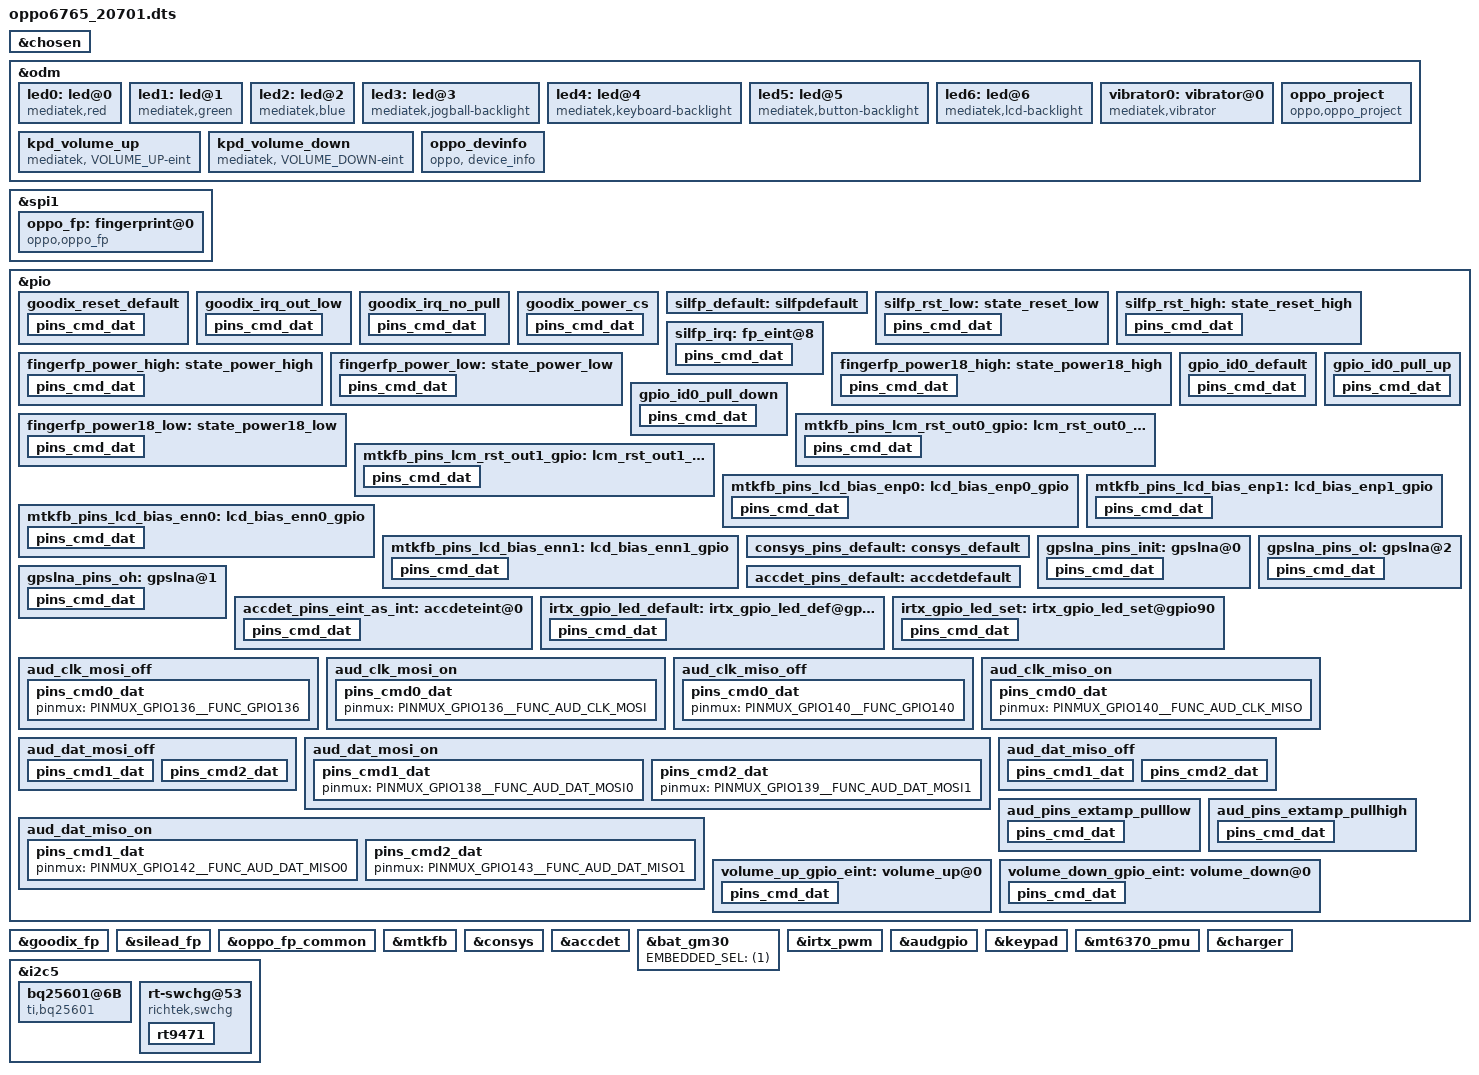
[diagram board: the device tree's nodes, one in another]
/*
 * Copyright (C) 2019 MediaTek Inc.
 *
 * This program is free software; you can redistribute it and/or modify
 * it under the terms of the GNU General Public License version 2 as
 * published by the Free Software Foundation.
 *
 * This program is distributed in the hope that it will be useful,
 * but WITHOUT ANY WARRANTY; without even the implied warranty of
 * MERCHANTABILITY or FITNESS FOR A PARTICULAR PURPOSE.
 * See http://www.gnu.org/licenses/gpl-2.0.html for more details.
 */

#include <dt-bindings/interrupt-controller/arm-gic.h>
#include <dt-bindings/interrupt-controller/irq.h>
#include <dt-bindings/pinctrl/mt6765-pinfunc.h>
#include <dt-bindings/clock/mt6765-clk.h>

/dts-v1/;
/plugin/;

/* chosen */
&chosen {

	/* fpga may has no lk, we need to specify display info here */
	/* fb buffer is reserved using this dts by memory node above */
	atag,videolfb-fb_base_h = <0x0>;
	atag,videolfb-fb_base_l = <0x5e605000>;
	atag,videolfb-islcmfound = <1>;
	/* because no lk, so lcm is not inited */
	atag,videolfb-islcm_inited = <0>;
	atag,videolfb-fps= <6000>;
	atag,videolfb-vramSize= <0x017bb000>;
	atag,videolfb-lcmname= "nt35695B_fhd_dsi_cmd_auo_rt5081_drv";
};

&odm {
	led0:led@0 {
		compatible = "mediatek,red";
		led_mode = <0>;
		data = <1>;
		pwm_config = <0 0 0 0 0>;
	};
	led1:led@1 {
		compatible = "mediatek,green";
		led_mode = <0>;
		data = <1>;
		pwm_config = <0 0 0 0 0>;
	};
	led2:led@2 {
		compatible = "mediatek,blue";
		led_mode = <0>;
		data = <1>;
		pwm_config = <0 0 0 0 0>;
	};
	led3:led@3 {
		compatible = "mediatek,jogball-backlight";
		led_mode = <0>;
		data = <1>;
		pwm_config = <0 0 0 0 0>;
	};
	led4:led@4 {
		compatible = "mediatek,keyboard-backlight";
		led_mode = <0>;
		data = <1>;
		pwm_config = <0 0 0 0 0>;
	};
	led5:led@5 {
		compatible = "mediatek,button-backlight";
		led_mode = <0>;
		data = <1>;
		pwm_config = <0 0 0 0 0>;
	};
	led6:led@6 {
		compatible = "mediatek,lcd-backlight";
	//#ifndef ODM_HQ_EDIT
	//wangcheng@ODM.Multimedia.LCD  2020/08/31 modify for lcd-bl mode
	led_mode = <4>;
	//#endif
		data = <1>;
		pwm_config = <0 3 0 0 0>;
	};
	vibrator0:vibrator@0 {
		compatible = "mediatek,vibrator";
		/*
		vib_timer = <25>;
		vib_limit = <9>;
		vib_vol= <9>;
		*/
		vib_timer = <30>;
		vib_limit = <0>;
                vib_vol= <11>;		
	};

	oppo_project:oppo_project {
		compatible = "oppo,oppo_project";
	};
//#ifdef VENDOR_EDIT
/* Bin.Li@EXP.BSP.bootloader.bootflow, 2017/05/16, Add volume up and down */
       kpd_volume_up:kpd_volume_up {
               compatible = "mediatek, VOLUME_UP-eint";
               interrupt-parent = <&pio>;
               interrupts = <20 IRQ_TYPE_EDGE_FALLING 20 0>;
               debounce = <32000>;
               status = "okay";
       };

       kpd_volume_down:kpd_volume_down {
               compatible = "mediatek, VOLUME_DOWN-eint";
               interrupt-parent = <&pio>;
               interrupts = <94 IRQ_TYPE_EDGE_FALLING 94 0>;
               debounce = <32000>;
               status = "okay";
       };
//#endif
	oppo_devinfo:oppo_devinfo {
		compatible = "oppo, device_info";
		sub_board-gpio = <&pio 43 0>;
		sdcard-gpio = <&pio 1 0>;
	};
};

&spi1 {
	#address-cells = <1>;
	#size-cells = <0>;
	status = "okay";
	oppo_fp: fingerprint@0 {
	    compatible = "oppo,oppo_fp";
	    reg = <0>;
	    spi-max-frequency = <8000000>;
	    netlink-event = <30>;
	    spi-id = <1>;
	    spi-irq = <122>;
	    spi-reg = <0x11010000>;
        status = "okay";
    };
};
&pio {
	goodix_reset_default: goodix_reset_default {
		pins_cmd_dat {
			pinmux = <PINMUX_GPIO171__FUNC_GPIO171>;
			slew-rate = <1>;
			output-low;
		};
	};
	goodix_irq_out_low: goodix_irq_out_low {
		pins_cmd_dat {
			pinmux = <PINMUX_GPIO3__FUNC_GPIO3>;
			slew-rate = <1>;
			output-low;
		};
	};
	goodix_irq_no_pull: goodix_irq_no_pull {
		pins_cmd_dat {
			pinmux = <PINMUX_GPIO3__FUNC_GPIO3>;
			slew-rate = <0>;
			bias-disable;
		};
	};
	goodix_power_cs: goodix_power_cs {
		pins_cmd_dat {
			pinmux = <PINMUX_GPIO158__FUNC_GPIO158>;
			slew-rate = <1>;
			bias-disable;
			output-high;
		};
	};    
};
&goodix_fp {
	pinctrl-names = "goodix_reset_default", "goodix_irq_out_low", "goodix_irq_no_pull", "goodix_power_cs";
	pinctrl-0 = <&goodix_reset_default>;
	pinctrl-1 = <&goodix_irq_out_low>;
	pinctrl-2 = <&goodix_irq_no_pull>;
    pinctrl-3 = <&goodix_power_cs>;
	interrupt-parent = <&pio>;
	interrupts = <3 0>;
	goodix,gpio_irq = <&pio 3 0x00>;
	goodix,gpio_reset = <&pio 171 0x00>;
    goodix,vdd-en = <&pio 158 0x00>;
	spi-max-frequency = <8000000>;
	status = "okay";
};

/*-------------------the goodix device config end----------------------*/

/*-------------------the silead device config start----------------------*/
&pio {
	silfp_default: silfpdefault {
	};
	silfp_rst_low: state_reset_low {
		pins_cmd_dat {
			pinmux = <PINMUX_GPIO171__FUNC_GPIO171>;
			slew-rate = <1>;
			output-low;
		};
	};
	silfp_rst_high: state_reset_high {
		pins_cmd_dat {
			pinmux = <PINMUX_GPIO171__FUNC_GPIO171>;
			slew-rate = <1>;
			output-high;
		};
	};
	silfp_irq: fp_eint@8 {
		pins_cmd_dat {
			pinmux = <PINMUX_GPIO3__FUNC_GPIO3>;
			slew-rate = <0>;
			bias-disable;
		};
	};
	fingerfp_power_high: state_power_high {
		pins_cmd_dat {
			pinmux = <PINMUX_GPIO158__FUNC_GPIO158>;
			slew-rate = <1>;
			output-high;
		};
	};

	fingerfp_power_low: state_power_low {
		pins_cmd_dat {
			pinmux = <PINMUX_GPIO158__FUNC_GPIO158>;
			slew-rate = <1>;
			output-low;
		};
	};
	fingerfp_power18_high: state_power18_high {
		pins_cmd_dat {
			pinmux = <PINMUX_GPIO158__FUNC_GPIO158>;
			slew-rate = <1>;
			output-high;
		};
	};

	fingerfp_power18_low: state_power18_low {
		pins_cmd_dat {
			pinmux = <PINMUX_GPIO79__FUNC_GPIO79>;
			slew-rate = <1>;
			output-low;
		};
	};
};
&silead_fp {
	pinctrl-names = "default", "rst-low", "rst-high",
	                "irq-init", "power_high","power_low", "power18_high","power18_low";
	pinctrl-0 = <&silfp_default>;
	pinctrl-1 = <&silfp_rst_low>;
	pinctrl-2 = <&silfp_rst_high>;
	pinctrl-3 = <&silfp_irq>;
	pinctrl-4 = <&fingerfp_power_high>;
	pinctrl-5 = <&fingerfp_power_low>;
	pinctrl-6 = <&fingerfp_power18_high>;
	pinctrl-7 = <&fingerfp_power18_low>;
	status = "okay";
};
/*-------------------the silead device config end----------------------*/

/*the fingerprint_id config to project dts.*/
&pio{
	gpio_id0_default: gpio_id0_default {
		pins_cmd_dat {
			pinmux = <PINMUX_GPIO170__FUNC_GPIO170>;
			slew-rate = <0>;
			bias-pull-up = <00>;
		};
	};
	gpio_id0_pull_up: gpio_id0_pull_up {
		pins_cmd_dat {
			pinmux = <PINMUX_GPIO170__FUNC_GPIO170>;
			slew-rate = <0>;
			bias-pull-up = <00>;
		};
	};
	gpio_id0_pull_down: gpio_id0_pull_down {
		pins_cmd_dat {
			pinmux = <PINMUX_GPIO170__FUNC_GPIO170>;
			slew-rate = <0>;
			bias-pull-down = <00>;
		};
	};
};

&oppo_fp_common {
	oppo,fp-id0 = <&pio 170 0x00>;
	oppo,fp-id1 = <&pio 173 0x00>;
	pinctrl-names = "default", "gpio_id0_pull_up", "gpio_id0_pull_down";
	pinctrl-0 = <&gpio_id0_default>;
	pinctrl-1 = <&gpio_id0_pull_up>;
	pinctrl-2 = <&gpio_id0_pull_down>;
};

/* TOUCH start */
/*&touch {
	tpd-resolution = <720 1600>;
	use-tpd-button = <0>;
	tpd-key-num = <3>;
	tpd-key-local= <139 172 158 0>;
	tpd-key-dim-local = <90 883 100 40 230
				 883 100 40 370 883 100 40 0 0 0 0>;
	tpd-max-touch-num = <5>;
	tpd-filter-enable = <0>;
	tpd-filter-pixel-density = <146>;
	tpd-filter-custom-prameters = <0 0 0 0 0 0 0 0 0 0 0 0>;
	tpd-filter-custom-speed = <0 0 0>;
	pinctrl-names = "default", "state_eint_as_int", "state_eint_output0",
		"state_eint_output1", "state_rst_output0", "state_rst_output1";
	pinctrl-0 = <&ctp_pins_default>;
	pinctrl-1 = <&ctp_pins_eint_as_int>;
	pinctrl-2 = <&ctp_pins_eint_output0>;
	pinctrl-3 = <&ctp_pins_eint_output1>;
	pinctrl-4 = <&ctp_pins_rst_output0>;
	pinctrl-5 = <&ctp_pins_rst_output1>;
	status = "okay";
};
&pio {
	ctp_pins_default: eint0default {
	};
	ctp_pins_eint_as_int: eint@0 {
		pins_cmd_dat {
			pinmux = <PINMUX_GPIO0__FUNC_GPIO0>;
			slew-rate = <0>;
			bias-disable;
		};
	};
	ctp_pins_eint_output0: eintoutput0 {
		pins_cmd_dat {
			pinmux = <PINMUX_GPIO0__FUNC_GPIO0>;
			slew-rate = <1>;
			output-low;
		};
	};
	ctp_pins_eint_output1: eintoutput1 {
		pins_cmd_dat {
			pinmux = <PINMUX_GPIO0__FUNC_GPIO0>;
			slew-rate = <1>;
			output-high;
		};
	};
	ctp_pins_rst_output0: rstoutput0 {
		pins_cmd_dat {
			pinmux = <PINMUX_GPIO178__FUNC_GPIO178>;
			slew-rate = <1>;
			output-low;
		};
	};
	ctp_pins_rst_output1: rstoutput1 {
		pins_cmd_dat {
			pinmux = <PINMUX_GPIO178__FUNC_GPIO178>;
			slew-rate = <1>;
			output-high;
		};
	};
};*/

//#ifdef ODM_HQ_EDIT
//#Fengkui@ODM_HQ.BSP.Touchscreen.Base,2020/09/08,bringup add for txd touchscreen mould dts config.
//&spi2{
//    #address-cells = <1>;
//    #size-cells = <0>;

//    touch_ts@0 {
//        reg = <0>;
//        compatible = "ilitek,ilitek-ts-spi","novatek,NVT-ts-spi";
//        spi-max-frequency = <9600000>;
//        status = "okay";
//        /* touch spi config */
//		touch,reset-gpio = <&pio 178 0x00>;
//		touch,irq-gpio = <&pio 0 0x2002>;
//		novatek,reset-gpio = <&pio 178 0x00>;
//		novatek,irq-gpio = <&pio 0 0x2002>;
//		novatek,swrst-n8-addr = <0x03F0FE>;
//              };
//     };
//#endif
/* TOUCH end */

/* wangcheng@ODM.Multimedia.LCD  2020/08/31 add  for lcd  bringup  start  */
/* DISPSYS GPIO standardization */
&pio {
	mtkfb_pins_lcm_rst_out0_gpio: lcm_rst_out0_gpio {
		pins_cmd_dat {
			pinmux = <PINMUX_GPIO45__FUNC_GPIO45>;
			slew-rate = <1>;
			output-low;
		};
	};
	
	mtkfb_pins_lcm_rst_out1_gpio: lcm_rst_out1_gpio {
		pins_cmd_dat {
			pinmux = <PINMUX_GPIO45__FUNC_GPIO45>;
			slew-rate = <1>;
			output-high;
		};
	};

	mtkfb_pins_lcd_bias_enp0: lcd_bias_enp0_gpio {
		pins_cmd_dat {
			pinmux = <PINMUX_GPIO166__FUNC_GPIO166>;
			slew-rate = <1>;
			output-low;
		};
	};

	mtkfb_pins_lcd_bias_enp1: lcd_bias_enp1_gpio {
		pins_cmd_dat {
			pinmux = <PINMUX_GPIO166__FUNC_GPIO166>;
			slew-rate = <1>;
			output-high;
		};
	};

	mtkfb_pins_lcd_bias_enn0: lcd_bias_enn0_gpio {
		pins_cmd_dat {
			pinmux = <PINMUX_GPIO165__FUNC_GPIO165>;
			slew-rate = <1>;
			output-low;
		};
	};

	mtkfb_pins_lcd_bias_enn1: lcd_bias_enn1_gpio {
		pins_cmd_dat {
			pinmux = <PINMUX_GPIO165__FUNC_GPIO165>;
			slew-rate = <1>;
			output-high;
		};
	};
};

&mtkfb {
	pinctrl-names = "lcm_rst_out0_gpio", "lcm_rst_out1_gpio",
		"lcd_bias_enp0_gpio", "lcd_bias_enp1_gpio", 
		 "lcd_bias_enn0_gpio", "lcd_bias_enn1_gpio";
	pinctrl-0 = <&mtkfb_pins_lcm_rst_out0_gpio>;
	pinctrl-1 = <&mtkfb_pins_lcm_rst_out1_gpio>;
	pinctrl-2 = <&mtkfb_pins_lcd_bias_enp0>;
	pinctrl-3 = <&mtkfb_pins_lcd_bias_enp1>;
	pinctrl-4 = <&mtkfb_pins_lcd_bias_enn0>;
	pinctrl-5 = <&mtkfb_pins_lcd_bias_enn1>;
	status = "okay";
};

/* DISPSYS GPIO standardization end */
/* wangcheng@ODM.Multimedia.LCD  2020/08/31 add  for lcd  bringup  end  */

/* CONSYS GPIO standardization */
&pio {
	consys_pins_default: consys_default {
	};
	gpslna_pins_init: gpslna@0 {
		pins_cmd_dat {
			pinmux = <PINMUX_GPIO91__FUNC_GPIO91>;
			slew-rate = <1>;
			bias-disable;
			output-low;
		};
	};
	gpslna_pins_oh: gpslna@1 {
		pins_cmd_dat {
			pinmux = <PINMUX_GPIO91__FUNC_GPIO91>;
			slew-rate = <1>;
			output-high;
		};
	};
	gpslna_pins_ol: gpslna@2 {
		pins_cmd_dat {
			pinmux = <PINMUX_GPIO91__FUNC_GPIO91>;
			slew-rate = <1>;
			output-low;
		};
	};
};
&consys {
	pinctrl-names = "default", "gps_lna_state_init",
		"gps_lna_state_oh", "gps_lna_state_ol";
	pinctrl-0 = <&consys_pins_default>;
	pinctrl-1 = <&gpslna_pins_init>;
	pinctrl-2 = <&gpslna_pins_oh>;
	pinctrl-3 = <&gpslna_pins_ol>;
	status = "okay";
};
/* CONSYS end */

/* accdet start */
&accdet {
	/* qiantao@PSW.MM.AudioDriver.Feature, 2020/12/03, setting headset micbias1 voltage to 2.7v*/
	accdet-mic-vol = <7>;
	headset-mode-setting = <0x500 0x500 1 0x1f0 0x800 0x800 0x20 0x44>;
	accdet-plugout-debounce = <1>;
	accdet-mic-mode = <1>;
	headset-eint-level-pol = <8>;
	headset-three-key-threshold = <0 80 220 400>;
	headset-three-key-threshold-CDD = <0 121 192 600>;
	headset-four-key-threshold = <0 58 121 192 400>;
	pinctrl-names = "default", "state_eint_as_int";
	pinctrl-0 = <&accdet_pins_default>;
	pinctrl-1 = <&accdet_pins_eint_as_int>;
	status = "okay";
};
&pio {
	accdet_pins_default: accdetdefault {
	};
	accdet_pins_eint_as_int: accdeteint@0 {
		pins_cmd_dat {
			pinmux = <PINMUX_GPIO9__FUNC_GPIO9>;
			slew-rate = <0>;
			bias-disable;
		};
	};
};
/* accdet end */
/* battery end */
&bat_gm30 {
	EMBEDDED_SEL = <(1)>;
};
/* battery end */
/* IRTX GPIO end */
&irtx_pwm {
	pinctrl-names = "irtx_gpio_led_default", "irtx_gpio_led_set";
	pinctrl-0 = <&irtx_gpio_led_default>;
	pinctrl-1 = <&irtx_gpio_led_set>;
	status = "okay";
};
&pio {
	irtx_gpio_led_default:irtx_gpio_led_def@gpio90 {
		pins_cmd_dat {
			pinmux = <PINMUX_GPIO90__FUNC_GPIO90>;
			slew-rate = <1>;
			bias-disable;
			output-low;
			input-schmitt-enable = <0>;
		};
	};

	irtx_gpio_led_set:irtx_gpio_led_set@gpio90 {
		pins_cmd_dat {
			pinmux = <PINMUX_GPIO90__FUNC_PWM0>;
			slew-rate = <1>;
			output-high;
		};
	};
};
/* IRTX GPIO Settings -End */

/* AUDIO GPIO standardization */
&audgpio {
	pinctrl-names = "aud_clk_mosi_off",
			"aud_clk_mosi_on",
			"aud_clk_miso_off",
			"aud_clk_miso_on",
			"aud_dat_mosi_off",
			"aud_dat_mosi_on",
			"aud_dat_miso_off",
			"aud_dat_miso_on",
			//#ifdef ODM_HQ_EDIT
			//zhoufeng@ODM.HQ.Multimedia.Audio 2020/09/06 modified for audio bringup
			"extamp-pulllow",
                        "extamp-pullhigh";
			//#endif /* ODM_HQ_EDIT */
	pinctrl-0 = <&aud_clk_mosi_off>;
	pinctrl-1 = <&aud_clk_mosi_on>;
	pinctrl-2 = <&aud_clk_miso_off>;
	pinctrl-3 = <&aud_clk_miso_on>;
	pinctrl-4 = <&aud_dat_mosi_off>;
	pinctrl-5 = <&aud_dat_mosi_on>;
	pinctrl-6 = <&aud_dat_miso_off>;
	pinctrl-7 = <&aud_dat_miso_on>;
	//#ifdef ODM_HQ_EDIT
	//zhoufeng@ODM.HQ.Multimedia.Audio 2020/03/04 modified for audio bringup
	pinctrl-8 = <&aud_pins_extamp_pulllow>;
	pinctrl-9 = <&aud_pins_extamp_pullhigh>;
	//#endif /* ODM_HQ_EDIT */
	status = "okay";
};

&pio {
	aud_clk_mosi_off: aud_clk_mosi_off {
		pins_cmd0_dat {
			pinmux = <PINMUX_GPIO136__FUNC_GPIO136>;
		};
	};

	aud_clk_mosi_on: aud_clk_mosi_on {
		pins_cmd0_dat {
			pinmux = <PINMUX_GPIO136__FUNC_AUD_CLK_MOSI>;
		};
	};

	aud_clk_miso_off: aud_clk_miso_off {
		pins_cmd0_dat {
			pinmux = <PINMUX_GPIO140__FUNC_GPIO140>;
		};
	};

	aud_clk_miso_on: aud_clk_miso_on {
		pins_cmd0_dat {
			pinmux = <PINMUX_GPIO140__FUNC_AUD_CLK_MISO>;
		};
	};

	aud_dat_mosi_off: aud_dat_mosi_off {
		pins_cmd1_dat {
			pinmux = <PINMUX_GPIO138__FUNC_GPIO138>;
			input-enable;
			slew-rate = <0>;
			bias-disable;
		};
		pins_cmd2_dat {
			pinmux = <PINMUX_GPIO139__FUNC_GPIO139>;
			input-enable;
			slew-rate = <0>;
			bias-disable;
		};
	};

	aud_dat_mosi_on: aud_dat_mosi_on {
		pins_cmd1_dat {
			pinmux = <PINMUX_GPIO138__FUNC_AUD_DAT_MOSI0>;
		};
		pins_cmd2_dat {
			pinmux = <PINMUX_GPIO139__FUNC_AUD_DAT_MOSI1>;
		};
	};

	aud_dat_miso_off: aud_dat_miso_off {
		pins_cmd1_dat {
			pinmux = <PINMUX_GPIO142__FUNC_GPIO142>;
			input-enable;
			slew-rate = <0>;
			bias-disable;
		};
		pins_cmd2_dat {
			pinmux = <PINMUX_GPIO143__FUNC_GPIO143>;
			input-enable;
			slew-rate = <0>;
			bias-disable;
		};
	};

	aud_dat_miso_on: aud_dat_miso_on {
		pins_cmd1_dat {
			pinmux = <PINMUX_GPIO142__FUNC_AUD_DAT_MISO0>;
		};
		pins_cmd2_dat {
			pinmux = <PINMUX_GPIO143__FUNC_AUD_DAT_MISO1>;
		};
	};

	//#ifdef ODM_HQ_EDIT
	//zhoufeng@ODM.HQ.Multimedia.Audio 2020/09/06 modified for audio bringup
        aud_pins_extamp_pulllow: aud_pins_extamp_pulllow {
		pins_cmd_dat {
				pinmux = <PINMUX_GPIO150__FUNC_GPIO150>;
				slew-rate = <1>;
				output-low;
		};
	};

	aud_pins_extamp_pullhigh: aud_pins_extamp_pullhigh {
		pins_cmd_dat {
				pinmux = <PINMUX_GPIO150__FUNC_GPIO150>;
				slew-rate = <1>;
				output-high;
		};
	};
	//#endif /* ODM_HQ_EDIT */
};
/* AUDIO end */

//#ifdef VENDOR_EDIT
/* Bin.Li@EXP.BSP.bootloader.bootflow, 2017/05/16, Add volume up and down */
&keypad {
	keypad,volume-up	= <&pio 20 0x00>;
	keypad,volume-down	= <&pio 94 0x00>;
	pinctrl-names = "volume_up_as_int", "volume_down_as_int";
	pinctrl-0 = <&volume_up_gpio_eint>;
	pinctrl-1 = <&volume_down_gpio_eint>;
	status = "okay";
};

&pio {
	volume_up_gpio_eint:volume_up@0{
		pins_cmd_dat {
			pinmux = <PINMUX_GPIO20__FUNC_GPIO20>;
			slew-rate = <0>;  /*direction 0:in, 1:out*/
			bias-pull-up = <00>;
			input-enable;
		};
	};
	volume_down_gpio_eint:volume_down@0{
		pins_cmd_dat {
			pinmux = <PINMUX_GPIO94__FUNC_GPIO94>;
			slew-rate = <0>;  /*direction 0:in, 1:out*/
			bias-pull-up = <00>;
			input-enable;
		};
	};
};
//#endif /*VENDOR_EDIT*/

&mt6370_pmu {
	mt6370,intr_gpio_num = <11>; /* direct defined GPIO num */
	mt6370,intr_gpio = <&pio 11 0x0>;
};

//&mt6370_typec {
//	mt6370pd,intr_gpio_num = <41>; /* direct defined GPIO num */
//	mt6370pd,intr_gpio = <&pio 41 0x0>;
//};


&charger {
	algorithm_name = "SwitchCharging";
	chg1_ta_ac_charger_current = <2000000>;
	chg2_ta_ac_charger_current = <2000000>;
};
&i2c5 {
	bq25601@6B {
			compatible = "ti,bq25601";
			reg = <0x6b>;
			ti,bq2560x,usb-vlim = <4600>;
			ti,bq2560x,usb-ilim = <500>;
			ti,bq2560x,usb-vreg = <4400>;
			ti,bq2560x,usb-ichg = <500>;
			ti,bq2560x,precharge-current = <256>;
			ti,bq2560x,termination-current = <240>;
			ti,bq2560x,boost-voltage = <4998>;
			ti,bq2560x,boost-current = <1200>;
			ti,bq2560x,enable_term;
			ti,bq2560x,stat-pin-ctrl = <3>;
			ti,bq2560x,vac-ovp-threshold = <6500>;
	};
	rt-swchg@53 {
			compatible = "richtek,swchg";
			reg = <0x53>;
			status = "okay";

			rt,intr_gpio_num = <11>; /* direct defined GPIO num */
			rt,intr_gpio = <&pio 11 0x0>; /* GPIO */
			rt9471 {
				/*
				* Charger name
				* Main charger: primary_chg
				* Slave charger: secondary_chg
				*/

				charger_name = "primary_chg";
				chg_alias_name = "rt9471_chg";
				rm-slave-addr = /bits/ 8 <0x53>;
				rm-name = "rt9471";
				interrupt-names = "wdt", "chg_mivr", "vbus_gd",
							"bc12_done", "detach", "vac_ov",
							"otg_fault", "chg_rdy", "chg_done";
				ichg = <1000000>;		/* uA */
				aicr = <500000>;		/* uA */
				mivr = <4200000>;		/* uV */
				cv = <4500000>;			/* uV */
				ieoc = <200000>;		/* uA */
				safe-tmr = <10>;		/* hour */
				wdt = <40>;			/* sec */
				/*
				* 0: MIVR register
				* 1: MIVR = VBAT + 200mV
				* 2: MIVR = VBAT + 250mV
				* >= 3: MIVR = VBAT + 300mV
				*/
				mivr-track = <0>;
				en-te;
				/* en-jeita; */
				/* ceb-invert; */
				/* dis-i2c-tout; */
				en-qon-rst;
				/* auto-aicr; */
			};
	};
};
#include <oppo6765_20701/cust.dtsi>
#include "cust_mt6765_camera_20701.dtsi"
/*End of this file, DO NOT ADD ANYTHING HERE*/

#include "tddi_tp_oppo6765.dtsi"
